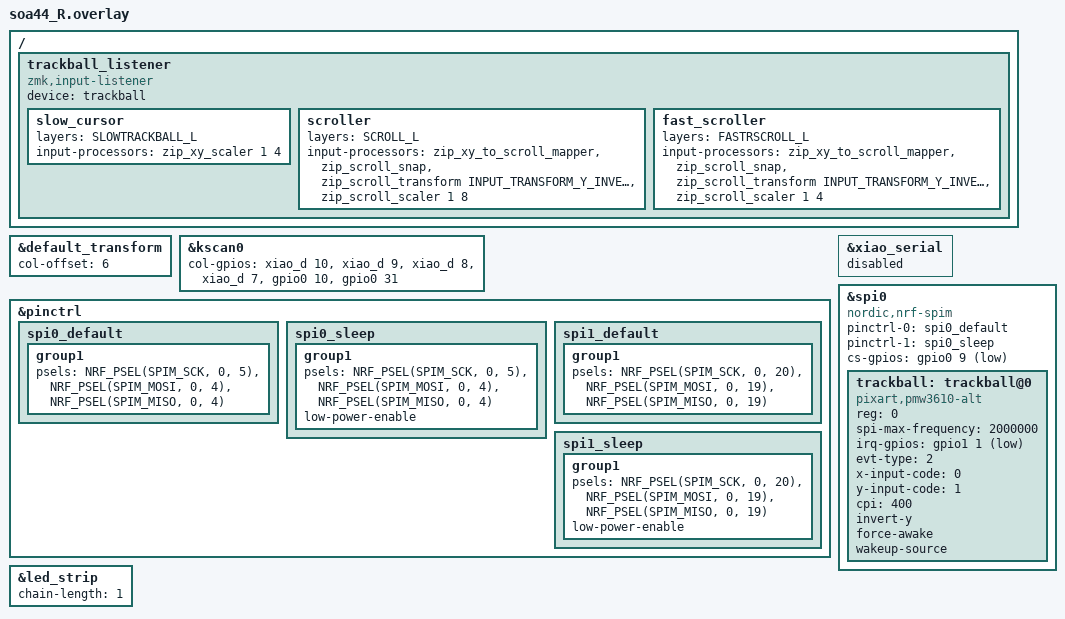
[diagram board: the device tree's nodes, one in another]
#include "soa44.dtsi"
#include <dt-bindings/zmk/input_transform.h>
#include <dt-bindings/input/input-event-codes.h>
#include <scroll-snap.dtsi> // スクロールスナップ ZMK Scroll Snap Module(https://github.com/kot149/zmk-scroll-snap)を使う
#include <input/processors.dtsi>
#include "../../../config/layers.dtsi"

&default_transform {
    col-offset = <6>;
};

&kscan0 {
        col-gpios
            = <&xiao_d 10 GPIO_ACTIVE_HIGH>
            , <&xiao_d 9 GPIO_ACTIVE_HIGH>
            , <&xiao_d 8 GPIO_ACTIVE_HIGH>
            , <&xiao_d 7 GPIO_ACTIVE_HIGH>
            , <&gpio0 10 GPIO_ACTIVE_HIGH>
            , <&gpio0 31 GPIO_ACTIVE_HIGH>
            ;
};

/ {
    trackball_listener {
        status = "okay";
        compatible = "zmk,input-listener";
        device = <&trackball>;
//        input-processors = <&zip_temp_layer 1 10000>; // 1(0から数えるので2番目)レイヤーに移動し、10000ms(=10秒)でAML抜ける

        // カーソル遅くする
        slow_cursor {
            layers = <SLOWTRACKBALL_L>;
            input-processors = <&zip_xy_scaler 1 4>;
        };

        scroller {
            layers = <SCROLL_L>;
            input-processors =
                <&zip_xy_to_scroll_mapper>,
                <&zip_scroll_snap>, // スクロールスナップ機能を入れる
                <&zip_scroll_transform INPUT_TRANSFORM_Y_INVERT>, // スクロール方向をWindowsに合わせる
                <&zip_scroll_scaler 1 8>; // スクロール速度を遅くする(2/5→1/8)
        };

        // 高速スクロール
        fast_scroller {
            layers = <FASTRSCROLL_L>;
            input-processors =
                <&zip_xy_to_scroll_mapper>,
                <&zip_scroll_snap>, // スクロールスナップ機能を入れる
                <&zip_scroll_transform INPUT_TRANSFORM_Y_INVERT>, // スクロール方向をWindowsに合わせる
                <&zip_scroll_scaler 1 4>; // スクロール速度調整(Soa44では1/8)
        };

    };
};

&pinctrl {
    spi0_default: spi0_default {
        group1 {
            psels = <NRF_PSEL(SPIM_SCK, 0, 5)>,
                <NRF_PSEL(SPIM_MOSI, 0, 4)>,
                <NRF_PSEL(SPIM_MISO, 0, 4)>;
        };
    };

    spi0_sleep: spi0_sleep {
        group1 {
            psels = <NRF_PSEL(SPIM_SCK, 0, 5)>,
                <NRF_PSEL(SPIM_MOSI, 0, 4)>,
                <NRF_PSEL(SPIM_MISO, 0, 4)>;
            low-power-enable;
        };
    };

    spi1_default: spi1_default {
        group1 {
            psels = <NRF_PSEL(SPIM_SCK, 0, 20)>,
                <NRF_PSEL(SPIM_MOSI, 0, 19)>,
                <NRF_PSEL(SPIM_MISO, 0, 19)>;
        };
    };

    spi1_sleep: spi1_sleep {
        group1 {
            psels = <NRF_PSEL(SPIM_SCK, 0, 20)>,
                <NRF_PSEL(SPIM_MOSI, 0, 19)>,
                <NRF_PSEL(SPIM_MISO, 0, 19)>;
            low-power-enable;
        };
    };
};

&xiao_serial { status = "disabled"; };

&spi0 {
    status = "okay";
    compatible = "nordic,nrf-spim";
    pinctrl-0 = <&spi0_default>;
    pinctrl-1 = <&spi0_sleep>;
    pinctrl-names = "default", "sleep";
    cs-gpios = <&gpio0 9 GPIO_ACTIVE_LOW>;

    trackball: trackball@0 {
        status = "okay";
        compatible = "pixart,pmw3610-alt";
        reg = <0>;
        spi-max-frequency = <2000000>;
        irq-gpios = <&gpio1 1 (GPIO_ACTIVE_LOW | GPIO_PULL_UP)>;
        evt-type = <2>;  // INPUT_EV_REL
        x-input-code = <0>;  // INPUT_REL_X
        y-input-code = <1>;  // INPUT_REL_Y
        cpi = <400>;
        invert-y;
        force-awake;
        wakeup-source;
    };
};

// Override led_strip to set red color for right side
&led_strip {
    status = "okay";
    chain-length = <1>;
    // Pre-set WS2812 to red color (0xFF0000) for right side identification
};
